# MKE15Z7 register map
Vendor: Freescale Semiconductor, Inc.; Series: Kinetis_E; File version: 1.6
CPU: CM0PLUS r0p0, little endian, no MPU, no FPU, VTOR, 2 interrupt priority bits
Registers are 32-bit, read-write, reset 0x0 unless marked. A register's access mark holds for its fields unless they carry their own. Offsets are from the block's base; [hi:lo] are bit positions; {n}, {i} and the like mark numbered series; 'fields as' and 'values as' point back to an identical list.

## SCG — System Clock Generator
Base 0x40064000; register names take the prefix SCG_
0x00 VERID ro reset 0x1000000 — Version ID Register
  [31:0] VERSION — SCG Version Number
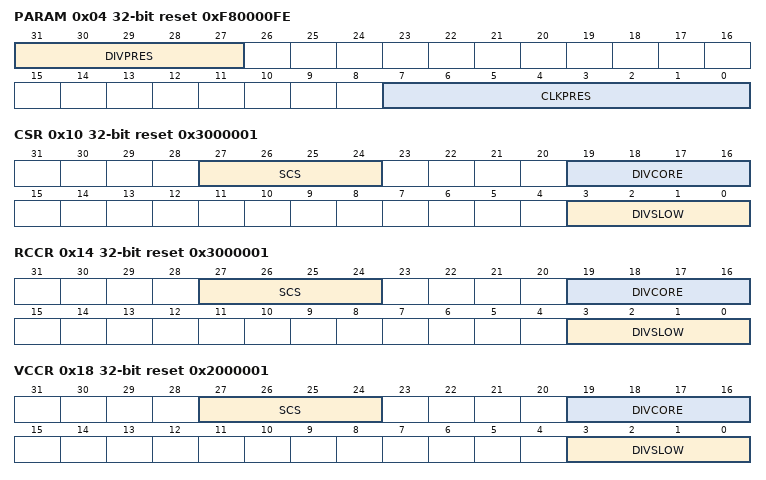
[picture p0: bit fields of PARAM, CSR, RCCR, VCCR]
0x04 PARAM ro reset 0xF80000FE — Parameter Register
  [31:27] DIVPRES — Divider Present
  [7:0] CLKPRES — Clock Present
0x10 CSR ro reset 0x3000001 — Clock Status Register
  [27:24] SCS — System Clock Source
    1=System OSC; 2=Slow IRC; 3=Fast IRC; 5=Low Power FLL (LPFLL)
  [19:16] DIVCORE — Core Clock Divide Ratio
    {v}=Divide-by-{v+1} (v=0..15)
  [3:0] DIVSLOW — Slow Clock Divide Ratio
    {v}=Divide-by-{v+1} (v=1..7)
0x14 RCCR reset 0x3000001 — Run Clock Control Register
  fields as CSR
0x18 VCCR reset 0x2000001 — VLPR Clock Control Register
  [27:24] SCS — System Clock Source
    1=System OSC; 2=Slow IRC
  [19:16] DIVCORE — Core Clock Divide Ratio
    {v}=Divide-by-{v+1} (v=0..15)
  [3:0] DIVSLOW — Slow Clock Divide Ratio
    {v}=Divide-by-{v+1} (v=1..7)
0x20 CLKOUTCNFG reset 0x3000000 — SCG CLKOUT Configuration Register
  [27:24] CLKOUTSEL — SCG Clkout Select
    0=SCG SLOW Clock; 1=System OSC; 2=Slow IRC; 3=Fast IRC; 5=Low Power FLL (LPFLL)
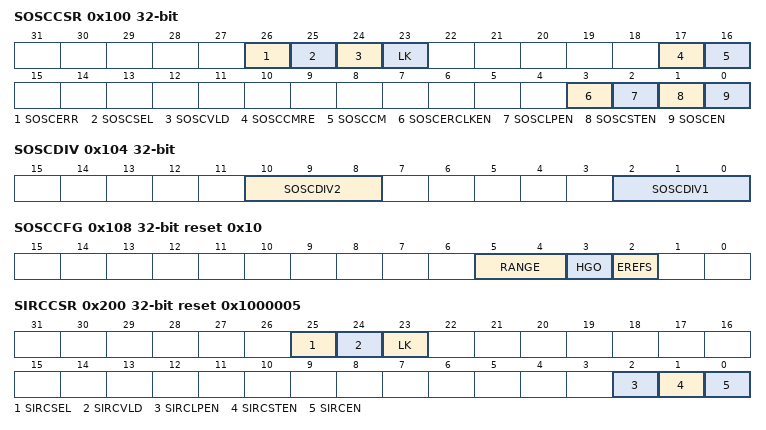
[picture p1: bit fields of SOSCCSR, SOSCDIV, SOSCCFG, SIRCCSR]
0x100 SOSCCSR — System OSC Control Status Register
  [26] SOSCERR — System OSC Clock Error
    0=System OSC Clock Monitor is disabled or has not detected an error; 1=System OSC Clock Monitor is enabled and detected an error
  [25] SOSCSEL ro — System OSC Selected
    0=System OSC is not the system clock source; 1=System OSC is the system clock source
  [24] SOSCVLD ro — System OSC Valid
    0=System OSC is not enabled or clock is not valid; 1=System OSC is enabled and output clock is valid
  [23] LK — Lock Register
    0=This Control Status Register can be written; 1=This Control Status Register cannot be written
  [17] SOSCCMRE — System OSC Clock Monitor Reset Enable
    0=Clock Monitor generates interrupt when error detected; 1=Clock Monitor generates reset when error detected
  [16] SOSCCM — System OSC Clock Monitor
    0=System OSC Clock Monitor is disabled; 1=System OSC Clock Monitor is enabled
  [3] SOSCERCLKEN — System OSC 3V ERCLK Enable
    0=System OSC 3V ERCLK output clock is disabled; 1=System OSC 3V ERCLK output clock is enabled when SYSOSC is enabled
  [2] SOSCLPEN — System OSC Low Power Enable
    0=System OSC is disabled in VLP modes; 1=System OSC is enabled in VLP modes
  [1] SOSCSTEN — System OSC Stop Enable
    0=System OSC is disabled in Stop modes; 1=System OSC is enabled in Stop modes if SOSCEN=1
  [0] SOSCEN — System OSC Enable
    0=System OSC is disabled; 1=System OSC is enabled
0x104 SOSCDIV — System OSC Divide Register
  [10:8] SOSCDIV2 — System OSC Clock Divide 2
    0=Output disabled; 1=Divide by 1; 2=Divide by 2; 3=Divide by 4; 4=Divide by 8; 5=Divide by 16; 6=Divide by 32; 7=Divide by 64
  [2:0] SOSCDIV1 — System OSC Clock Divide 1
    values as SOSCDIV2
0x108 SOSCCFG reset 0x10 — System Oscillator Configuration Register
  [5:4] RANGE — System OSC Range Select
    1=Low frequency range selected for the crystal oscillator of 32 kHz to 40 kHz; 2=Medium frequency range selected for the crytstal oscillator of 1 Mhz to 8 Mhz; 3=High frequency range selected for the crystal oscillator of 8 Mhz to 32 Mhz
  [3] HGO — High Gain Oscillator Select
    0=Configure crystal oscillaor for low-power operation; 1=Configure crystal oscillator for high-gain operation
  [2] EREFS — External Reference Select
    0=External reference clock selected; 1=Internal crystal oscillator of OSC requested
0x200 SIRCCSR reset 0x1000005 — Slow IRC Control Status Register
  [25] SIRCSEL ro — Slow IRC Selected
    0=Slow IRC is not the system clock source; 1=Slow IRC is the system clock source
  [24] SIRCVLD ro — Slow IRC Valid
    0=Slow IRC is not enabled or clock is not valid; 1=Slow IRC is enabled and output clock is valid
  [23] LK — Lock Register
    0=Control Status Register can be written; 1=Control Status Register cannot be written
  [2] SIRCLPEN — Slow IRC Low Power Enable
    0=Slow IRC is disabled in VLP modes; 1=Slow IRC is enabled in VLP modes
  [1] SIRCSTEN — Slow IRC Stop Enable
    0=Slow IRC is disabled in Stop modes; 1=Slow IRC is enabled in Stop modes
  [0] SIRCEN — Slow IRC Enable
    0=Slow IRC is disabled; 1=Slow IRC is enabled
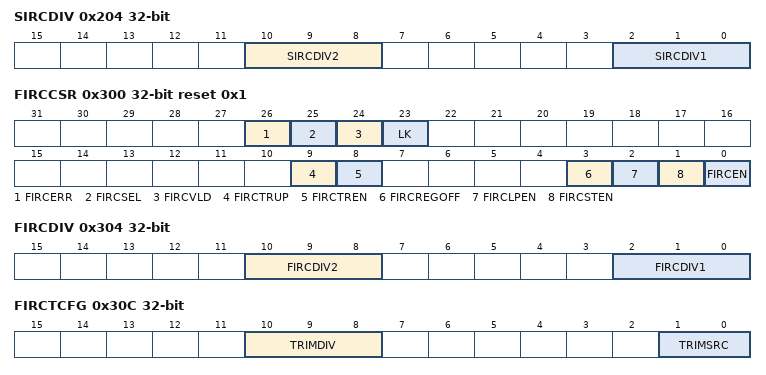
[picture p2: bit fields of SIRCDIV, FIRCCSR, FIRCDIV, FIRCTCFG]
0x204 SIRCDIV — Slow IRC Divide Register
  [10:8] SIRCDIV2 — Slow IRC Clock Divide 2
    values as SOSCDIV.SOSCDIV2
  [2:0] SIRCDIV1 — Slow IRC Clock Divide 1
    values as SOSCDIV.SOSCDIV2
0x208 SIRCCFG reset 0x1 — Slow IRC Configuration Register
  [0] RANGE — Frequency Range
    0=Slow IRC low range clock (2 MHz); 1=Slow IRC high range clock (8 MHz )
0x300 FIRCCSR reset 0x1 — Fast IRC Control Status Register
  [26] FIRCERR — Fast IRC Clock Error
    0=Error not detected with the Fast IRC trimming; 1=Error detected with the Fast IRC trimming
  [25] FIRCSEL ro — Fast IRC Selected status
    0=Fast IRC is not the system clock source; 1=Fast IRC is the system clock source
  [24] FIRCVLD ro — Fast IRC Valid status
    0=Fast IRC is not enabled or clock is not valid; 1=Fast IRC is enabled and output clock is valid
  [23] LK — Lock Register
    values as SIRCCSR.LK
  [9] FIRCTRUP — Fast IRC Trim Update
    0=Disable Fast IRC trimming updates; 1=Enable Fast IRC trimming updates
  [8] FIRCTREN — Fast IRC Trim Enable
    0=Disable trimming Fast IRC to an external clock source; 1=Enable trimming Fast IRC to an external clock source
  [3] FIRCREGOFF — Fast IRC Regulator Enable
    0=Fast IRC Regulator is enabled; 1=Fast IRC Regulator is disabled
  [2] FIRCLPEN — Fast IRC Low Power Enable
    0=Fast IRC is disabled in VLP modes; 1=Fast IRC is enabled in VLP modes
  [1] FIRCSTEN — Fast IRC Stop Enable
    0=Fast IRC is disabled in Stop modes. When selected as the reference clock to the System PLL and if the System PLL is enabled in STOP mode, the Fast IRC will stay enabled even if FIRCSTEN=0.; 1=Fast IRC is enabled in Stop modes
  [0] FIRCEN — Fast IRC Enable
    0=Fast IRC is disabled; 1=Fast IRC is enabled
0x304 FIRCDIV — Fast IRC Divide Register
  [10:8] FIRCDIV2 — Fast IRC Clock Divide 2
    values as SOSCDIV.SOSCDIV2
  [2:0] FIRCDIV1 — Fast IRC Clock Divide 1
    values as SOSCDIV.SOSCDIV2
0x308 FIRCCFG — Fast IRC Configuration Register
  [1:0] RANGE — Frequency Range
    0=Fast IRC is trimmed to 48 MHz; 1=Fast IRC is trimmed to 52 MHz; 2=Fast IRC is trimmed to 56 MHz; 3=Fast IRC is trimmed to 60 MHz
0x30C FIRCTCFG — Fast IRC Trim Configuration Register
  [10:8] TRIMDIV — Fast IRC Trim Predivide
    0=Divide by 1; 1=Divide by 128; 2=Divide by 256; 3=Divide by 512; 4=Divide by 1024; 5=Divide by 2048; 6=Reserved. Writing this value will result in Divide by 1.; 7=Reserved. Writing this value will result in a Divide by 1.
  [1:0] TRIMSRC — Trim Source
    2=System OSC
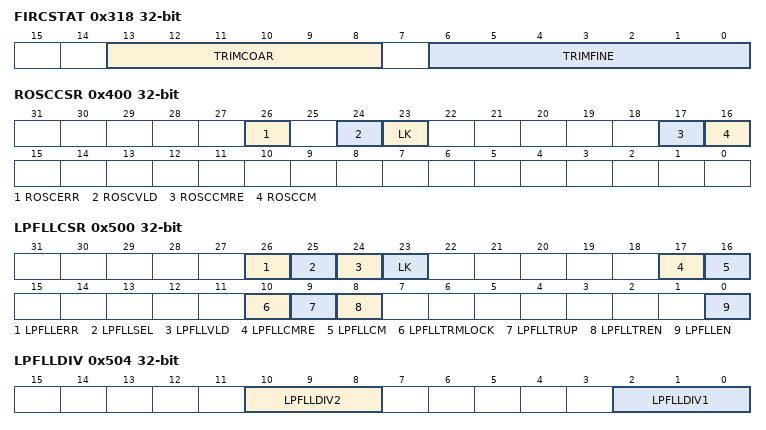
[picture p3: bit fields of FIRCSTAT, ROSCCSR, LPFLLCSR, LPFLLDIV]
0x318 FIRCSTAT — Fast IRC Status Register
  [13:8] TRIMCOAR — Trim Coarse
  [6:0] TRIMFINE — Trim Fine Status
0x400 ROSCCSR — RTC OSC Control Status Register
  [26] ROSCERR — RTC OSC Clock Error
    0=RTC OSC Clock Monitor is disabled or has not detected an error; 1=RTC OSC Clock Monitor is enabled and detected an RTC loss of clock error
  [24] ROSCVLD ro — RTC OSC Valid
    0=RTC OSC is not enabled or clock is not valid; 1=RTC OSC is enabled and output clock is valid
  [23] LK — Lock Register
    values as SIRCCSR.LK
  [17] ROSCCMRE — RTC OSC Clock Monitor Reset Enable
    values as SOSCCSR.SOSCCMRE
  [16] ROSCCM — RTC OSC Clock Monitor
    0=RTC OSC Clock Monitor is disabled; 1=RTC OSC Clock Monitor is enabled
0x500 LPFLLCSR — Low Power FLL Control Status Register
  [26] LPFLLERR — LPFLL Clock Error
    0=Error not detected with the LPFLL trimming; 1=Error detected with the LPFLL trimming
  [25] LPFLLSEL ro — LPFLL Selected
    0=LPFLL is not the system clock source; 1=LPFLL is the system clock source
  [24] LPFLLVLD ro — LPFLL Valid
    0=LPFLL is not enabled or clock is not valid; 1=LPFLL is enabled and output clock is valid
  [23] LK — Lock Register
    values as SIRCCSR.LK
  [17] LPFLLCMRE — LPFLL Clock Monitor Reset Enable
    values as SOSCCSR.SOSCCMRE
  [16] LPFLLCM — LPFLL Clock Monitor
    0=LPFLL Clock Monitor is disabled; 1=LPFLL Clock Monitor is enabled
  [10] LPFLLTRMLOCK ro — LPFLL Trim LOCK
    0=LPFLL not Locked; 1=LPFLL trimmed and Locked
  [9] LPFLLTRUP — LPFLL Trim Update
    0=Disable LPFLL trimming updates. LPFLL frequency determined by AUTOTRIM written value.; 1=Enable LPFLL trimming updates. LPFLL frequency determined by reference clock multiplication
  [8] LPFLLTREN — LPFLL Trim Enable
    0=Disable trimming LPFLL to an reference clock source; 1=Enable trimming LPFLL to an reference clock source
  [0] LPFLLEN — LPFLL Enable
    0=LPFLL is disabled; 1=LPFLL is enabled
0x504 LPFLLDIV — Low Power FLL Divide Register
  [10:8] LPFLLDIV2 — LPFLL Clock Divide 2
    values as SOSCDIV.SOSCDIV2
  [2:0] LPFLLDIV1 — LPFLL Clock Divide 1
    values as SOSCDIV.SOSCDIV2
0x508 LPFLLCFG — Low Power FLL Configuration Register
  [1:0] FSEL — Frequency Select
    0=LPFLL is trimmed to 48 MHz; 1=LPFLL is trimmed to 72 MHz
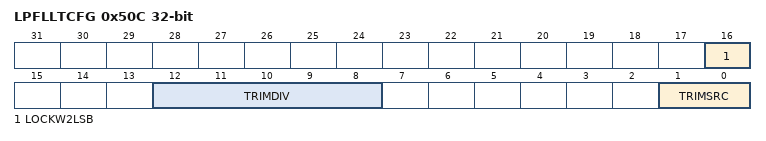
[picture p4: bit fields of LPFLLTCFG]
0x50C LPFLLTCFG — Low Power FLL Trim Configuration Register
  [16] LOCKW2LSB — Lock LPFLL with 2 LSBS
    0=LPFLL locks within 1LSB (0.4%); 1=LPFLL locks within 2LSB (0.8%)
  [12:8] TRIMDIV — LPFLL Trim Predivide
  [1:0] TRIMSRC — Trim Source
    0=SIRC; 1=FIRC; 2=System OSC; 3=RTC OSC
0x514 LPFLLSTAT — Low Power FLL Status Register
  [7:0] AUTOTRIM — Auto Tune Trim Status
